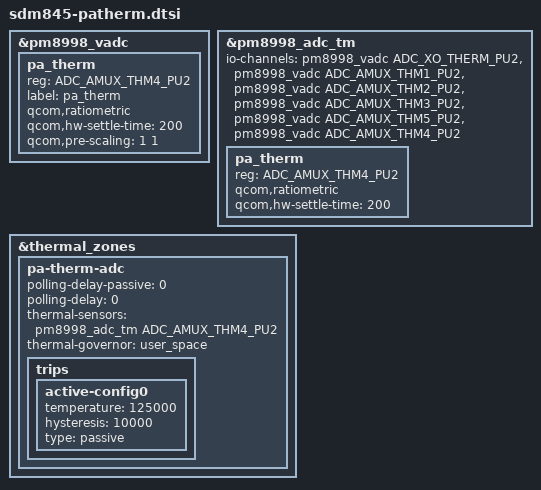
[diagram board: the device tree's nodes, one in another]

#include <dt-bindings/iio/qcom,spmi-vadc.h>

&pm8998_vadc {
	pa_therm {
		reg = <ADC_AMUX_THM4_PU2>;
		label = "pa_therm";
		qcom,ratiometric;
		qcom,hw-settle-time = <200>;
		qcom,pre-scaling = <1 1>;
	};
};

&pm8998_adc_tm {
	/* the whole list again: this extends sdm845-b1c1-thermal.dtsi */
	io-channels = <&pm8998_vadc ADC_XO_THERM_PU2>,
		      <&pm8998_vadc ADC_AMUX_THM1_PU2>,
		      <&pm8998_vadc ADC_AMUX_THM2_PU2>,
		      <&pm8998_vadc ADC_AMUX_THM3_PU2>,
		      <&pm8998_vadc ADC_AMUX_THM5_PU2>,
		      <&pm8998_vadc ADC_AMUX_THM4_PU2>;

	pa_therm {
		reg = <ADC_AMUX_THM4_PU2>;
		qcom,ratiometric;
		qcom,hw-settle-time = <200>;
	};
};

&thermal_zones {
	pa-therm-adc {
		polling-delay-passive = <0>;
		polling-delay = <0>;
		thermal-sensors = <&pm8998_adc_tm ADC_AMUX_THM4_PU2>;
		thermal-governor = "user_space";

		trips {
			active-config0 {
				temperature = <125000>;
				hysteresis = <10000>;
				type = "passive";
			};
		};
	};
};
